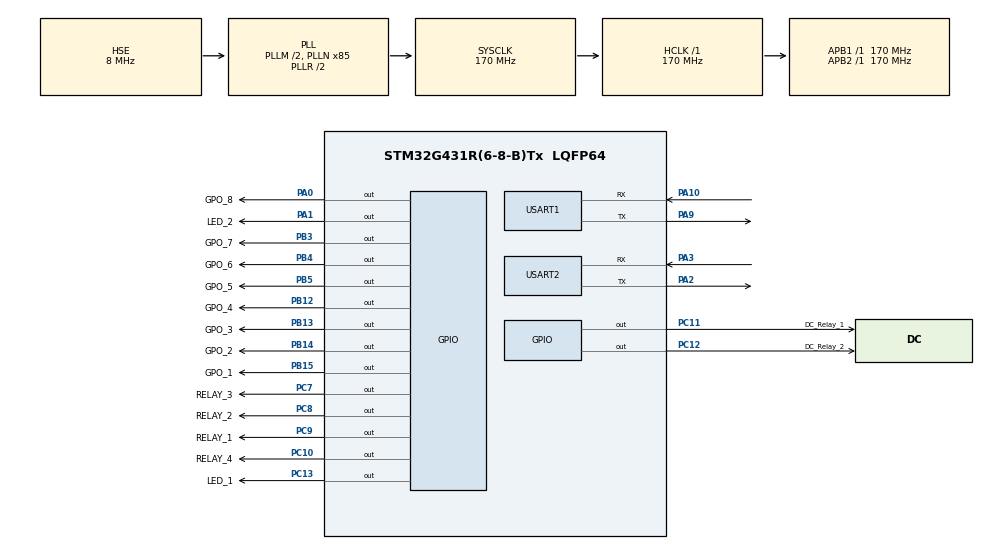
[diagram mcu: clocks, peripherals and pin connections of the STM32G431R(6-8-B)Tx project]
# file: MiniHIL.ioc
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FREERTOS.Queues01=uart1RxQueue,256,1,1,Dynamic,NULL,NULL
FREERTOS.Tasks01=defaultTask,16,512,StartDefaultTask,Default,NULL,Dynamic,NULL,NULL;Protocol_Task,24,1024,StartProtocol_Task,Default,NULL,Dynamic,NULL,NULL
FREERTOS.configTOTAL_HEAP_SIZE=9000
FREERTOS.configUSE_NEWLIB_REENTRANT=1
Mcu.Family=STM32G4
Mcu.Name=STM32G431R(6-8-B)Tx
Mcu.Package=LQFP64
NVIC.PriorityGroup=NVIC_PRIORITYGROUP_4
NVIC.TIM6_DAC_IRQn=true\:15\:0\:false\:false\:true\:false\:false\:true\:true
NVIC.TimeBase=TIM6_DAC_IRQn
NVIC.TimeBaseIP=TIM6
NVIC.USART1_IRQn=true\:5\:0\:false\:false\:true\:true\:true\:true\:true
PA0.GPIO_Label=GPO_8
PA0.Signal=GPIO_Output
PA1.GPIO_Label=LED_2
PA1.Signal=GPIO_Output
PA10.Mode=Asynchronous
PA10.Signal=USART1_RX
PA13.Mode=Serial_Wire
PA13.Signal=SYS_JTMS-SWDIO
PA14.Mode=Serial_Wire
PA14.Signal=SYS_JTCK-SWCLK
PA2.Mode=Asynchronous
PA2.Signal=USART2_TX
PA3.Mode=Asynchronous
PA3.Signal=USART2_RX
PA9.Mode=Asynchronous
PA9.Signal=USART1_TX
PB12.GPIO_Label=GPO_4
PB12.Signal=GPIO_Output
PB13.GPIO_Label=GPO_3
PB13.Signal=GPIO_Output
PB14.GPIO_Label=GPO_2
PB14.Signal=GPIO_Output
PB15.GPIO_Label=GPO_1
PB15.Signal=GPIO_Output
PB3.GPIO_Label=GPO_7
PB3.Signal=GPIO_Output
PB4.GPIO_Label=GPO_6
PB4.Signal=GPIO_Output
PB5.GPIO_Label=GPO_5
PB5.Signal=GPIO_Output
PC10.GPIO_Label=RELAY_4
PC10.Signal=GPIO_Output
PC11.GPIO_Label=DC_Relay_1
PC11.Signal=GPIO_Output
PC12.GPIO_Label=DC_Relay_2
PC12.Signal=GPIO_Output
PC13.GPIO_Label=LED_1
PC13.Signal=GPIO_Output
PC7.GPIO_Label=RELAY_3
PC7.Signal=GPIO_Output
PC8.GPIO_Label=RELAY_2
PC8.Signal=GPIO_Output
PC9.GPIO_Label=RELAY_1
PC9.Signal=GPIO_Output
PF0-OSC_IN.Mode=HSE-External-Oscillator
PF0-OSC_IN.Signal=RCC_OSC_IN
PF1-OSC_OUT.Mode=HSE-External-Oscillator
PF1-OSC_OUT.Signal=RCC_OSC_OUT
ProjectManager.HeapSize=0x200
ProjectManager.StackSize=0x400
ProjectManager.TargetToolchain=STM32CubeIDE
RCC.ADC12Freq_Value=170000000
RCC.AHBFreq_Value=170000000
RCC.APB1Freq_Value=170000000
RCC.APB1TimFreq_Value=170000000
RCC.APB2Freq_Value=170000000
RCC.APB2TimFreq_Value=170000000
RCC.CortexFreq_Value=170000000
RCC.EXTERNAL_CLOCK_VALUE=12288000
RCC.HCLKFreq_Value=170000000
RCC.HSE_VALUE=8000000
RCC.HSI48_VALUE=48000000
RCC.HSI_VALUE=16000000
RCC.LSE_VALUE=32768
RCC.PLLM=RCC_PLLM_DIV2
RCC.PLLN=85
RCC.PLLSourceVirtual=RCC_PLLSOURCE_HSE
RCC.SYSCLKFreq_VALUE=170000000
RCC.SYSCLKSource=RCC_SYSCLKSOURCE_PLLCLK
RCC.USBFreq_Value=170000000
RCC.VCOOutputFreq_Value=340000000
USART1.VirtualMode-Asynchronous=VM_ASYNC
USART2.VirtualMode-Asynchronous=VM_ASYNC
VP_FREERTOS_VS_CMSIS_V2.Mode=CMSIS_V2
VP_SYS_VS_DBSignals.Mode=DisableDeadBatterySignals
VP_SYS_VS_tim6.Mode=TIM6
board=custom

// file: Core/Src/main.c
/* USER CODE BEGIN Header */
/**
  ******************************************************************************
  * @file           : main.c
  * @brief          : Main program body
  ******************************************************************************
  * @attention
  *
  * Copyright (c) 2026 STMicroelectronics.
  * All rights reserved.
  *
  * This software is licensed under terms that can be found in the LICENSE file
  * in the root directory of this software component.
  * If no LICENSE file comes with this software, it is provided AS-IS.
  *
  ******************************************************************************
  */
/* USER CODE END Header */
#include "main.h"
#include "cmsis_os.h"
#include "usart.h"
#include "gpio.h"

void SystemClock_Config(void);
void MX_FREERTOS_Init(void);

int main(void)
{

  /* MCU Configuration--------------------------------------------------------*/

  /* Reset of all peripherals, Initializes the Flash interface and the Systick. */
  HAL_Init();

  /* Configure the system clock */
  SystemClock_Config();

  /* Initialize all configured peripherals */
  MX_GPIO_Init();
  MX_USART2_UART_Init();
  MX_USART1_UART_Init();

  /* Init scheduler */
  osKernelInitialize();  /* Call init function for freertos objects (in cmsis_os2.c) */
  MX_FREERTOS_Init();

  /* Start scheduler */
  osKernelStart();

  /* We should never get here as control is now taken by the scheduler */

  /* Infinite loop */
  while (1)
  {

  }
}

void SystemClock_Config(void)
{
  RCC_OscInitTypeDef RCC_OscInitStruct = {0};
  RCC_ClkInitTypeDef RCC_ClkInitStruct = {0};

  /** Configure the main internal regulator output voltage
  */
  HAL_PWREx_ControlVoltageScaling(PWR_REGULATOR_VOLTAGE_SCALE1_BOOST);

  /** Initializes the RCC Oscillators according to the specified parameters
  * in the RCC_OscInitTypeDef structure.
  */
  RCC_OscInitStruct.OscillatorType = RCC_OSCILLATORTYPE_HSE;
  RCC_OscInitStruct.HSEState = RCC_HSE_ON;
  RCC_OscInitStruct.PLL.PLLState = RCC_PLL_ON;
  RCC_OscInitStruct.PLL.PLLSource = RCC_PLLSOURCE_HSE;
  RCC_OscInitStruct.PLL.PLLM = RCC_PLLM_DIV2;
  RCC_OscInitStruct.PLL.PLLN = 85;
  RCC_OscInitStruct.PLL.PLLP = RCC_PLLP_DIV2;
  RCC_OscInitStruct.PLL.PLLQ = RCC_PLLQ_DIV2;
  RCC_OscInitStruct.PLL.PLLR = RCC_PLLR_DIV2;
  if (HAL_RCC_OscConfig(&RCC_OscInitStruct) != HAL_OK)
  {
    Error_Handler();
  }

  /** Initializes the CPU, AHB and APB buses clocks
  */
  RCC_ClkInitStruct.ClockType = RCC_CLOCKTYPE_HCLK|RCC_CLOCKTYPE_SYSCLK
                              |RCC_CLOCKTYPE_PCLK1|RCC_CLOCKTYPE_PCLK2;
  RCC_ClkInitStruct.SYSCLKSource = RCC_SYSCLKSOURCE_PLLCLK;
  RCC_ClkInitStruct.AHBCLKDivider = RCC_SYSCLK_DIV1;
  RCC_ClkInitStruct.APB1CLKDivider = RCC_HCLK_DIV1;
  RCC_ClkInitStruct.APB2CLKDivider = RCC_HCLK_DIV1;

  if (HAL_RCC_ClockConfig(&RCC_ClkInitStruct, FLASH_LATENCY_4) != HAL_OK)
  {
    Error_Handler();
  }
}

void HAL_TIM_PeriodElapsedCallback(TIM_HandleTypeDef *htim)
{
  if (htim->Instance == TIM6)
  {
    HAL_IncTick();
  }
}

void Error_Handler(void)
{
  __disable_irq();
  while (1)
  {
  }
}

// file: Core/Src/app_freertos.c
/* USER CODE BEGIN Header */
/**
  ******************************************************************************
  * File Name          : app_freertos.c
  * Description        : Code for freertos applications
  ******************************************************************************
  * @attention
  *
  * Copyright (c) 2026 STMicroelectronics.
  * All rights reserved.
  *
  * This software is licensed under terms that can be found in the LICENSE file
  * in the root directory of this software component.
  * If no LICENSE file comes with this software, it is provided AS-IS.
  *
  ******************************************************************************
  */
/* USER CODE END Header */

#include "FreeRTOS.h"
#include "task.h"
#include "main.h"
#include "cmsis_os.h"

/* USER CODE BEGIN Includes */
#include "app_tasks.h"

/* USER CODE END Includes */

/* Definitions for defaultTask */
osThreadId_t defaultTaskHandle;
const osThreadAttr_t defaultTask_attributes = {
  .name = "defaultTask",
  .priority = (osPriority_t) osPriorityBelowNormal,
  .stack_size = 512 * 4
};
/* Definitions for Protocol_Task */
osThreadId_t Protocol_TaskHandle;
const osThreadAttr_t Protocol_Task_attributes = {
  .name = "Protocol_Task",
  .priority = (osPriority_t) osPriorityNormal,
  .stack_size = 1024 * 4
};
/* Definitions for uart1RxQueue */
osMessageQueueId_t uart1RxQueueHandle;
const osMessageQueueAttr_t uart1RxQueue_attributes = {
  .name = "uart1RxQueue"
};

void StartDefaultTask(void *argument);
void StartProtocol_Task(void *argument);

void MX_FREERTOS_Init(void); /* (MISRA C 2004 rule 8.1) */

void MX_FREERTOS_Init(void) {

  /* Create the queue(s) */
  /* creation of uart1RxQueue */
  uart1RxQueueHandle = osMessageQueueNew (256, 1, &uart1RxQueue_attributes);

  /* Create the thread(s) */
  /* creation of defaultTask */
  defaultTaskHandle = osThreadNew(StartDefaultTask, NULL, &defaultTask_attributes);

  /* creation of Protocol_Task */
  Protocol_TaskHandle = osThreadNew(StartProtocol_Task, NULL, &Protocol_Task_attributes);

}

void StartDefaultTask(void *argument)
{
  /* USER CODE BEGIN StartDefaultTask */
  /* Infinite loop */
	AppHeartbeatTask(argument);
  /* USER CODE END StartDefaultTask */
}

void StartProtocol_Task(void *argument)
{
  /* USER CODE BEGIN StartProtocol_Task */
  /* Infinite loop */
  for(;;)
  {
	  vProtocolTask(argument);
    //osDelay(1);
  }
  /* USER CODE END StartProtocol_Task */
}
